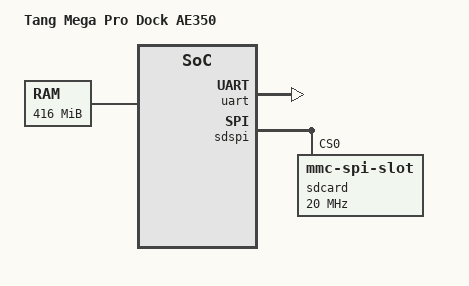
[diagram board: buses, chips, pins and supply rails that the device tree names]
// SPDX-License-Identifier: (GPL-2.0-or-later OR MIT)
/dts-v1/;
/ {
	#address-cells = <1>;
	#size-cells = <1>;
	compatible = "prodock,tang-console-138k";
	model = "Tang Mega Pro Dock AE350";
	aliases { serial0 = &uart; spi0 = &sdspi; mmc0 = &sdcard; };
	chosen { stdout-path = "serial0:115200n8"; };
	cpus {
		#address-cells = <1>;
		#size-cells = <0>;
		bootph-all;
		cpu@0 {
			device_type = "cpu";
			reg = <0>;
			compatible = "riscv";
			riscv,isa = "rv32imafdc_zicsr_zifencei";
			clock-frequency = <800000000>;
			mmu-type = "riscv,sv32";
			bootph-all;
		};
	};
	/* Preserve GPU pages and game resources below 96 MiB. */
	memory@6000000 { device_type = "memory"; reg = <0x06000000 0x1a000000>; bootph-all; };
	uart: serial@f0300000 {
		compatible = "andestech,uart16550", "ns16550a";
		reg = <0xf0300000 0x1000>;
		clock-frequency = <80000000>;
		reg-shift = <2>;
		reg-offset = <32>;
		no-loopback-test;
		bootph-all;
	};
	timer@e6000000 {
		compatible = "andestech,plmt0"; reg = <0xe6000000 0x1000>;
		clock-frequency = <80000000>; bootph-all;
	};
	sdspi: spi@f0f00000 {
		compatible = "mjx,prodock-atcspi200";
		reg = <0xf0f00000 0x100>, <0xf0700000 0x100>;
		#address-cells = <1>; #size-cells = <0>;
		sdcard: mmc@0 { compatible = "mmc-spi-slot"; reg = <0>;
			spi-max-frequency = <20000000>; };
	};
};
